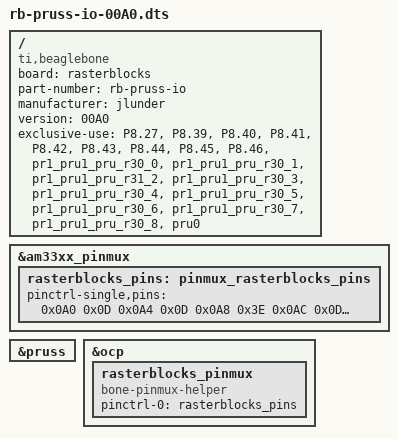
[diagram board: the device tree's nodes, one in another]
/dts-v1/;
/plugin/;

/ {
	compatible = "ti,beaglebone", "ti,beaglebone-black";
	board = "rasterblocks";
	part-number = "rb-pruss-io";
	manufacturer = "jlunder";
	version = "00A0";

	exclusive-use =
		"P8.27",
		"P8.39",
		"P8.40",
		"P8.41",
		"P8.42",
		"P8.43",
		"P8.44",
		"P8.45",
		"P8.46",
		"pr1_pru1_pru_r30_0",
		"pr1_pru1_pru_r30_1",
		"pr1_pru1_pru_r31_2",
		"pr1_pru1_pru_r30_3",
		"pr1_pru1_pru_r30_4",
		"pr1_pru1_pru_r30_5",
		"pr1_pru1_pru_r30_6",
		"pr1_pru1_pru_r30_7",
		"pr1_pru1_pru_r30_8",
		"pru0";

	fragment@0 {
		target = <&am33xx_pinmux>;
		__overlay__ {
			rasterblocks_pins: pinmux_rasterblocks_pins {
				pinctrl-single,pins = <
					0x0A0 0x0D  // P8_45: Mode 5 = pr1_pru1_pru_r30, disable pulldown, rx
					0x0A4 0x0D  // P8_46: Mode 5 = pr1_pru1_pru_r30, disable pulldown, rx
					0x0A8 0x3E  // P8_43: Mode 6 = pr1_pru1_pru_r31, disable pullup, enable rx
					0x0AC 0x0D  // P8_44: Mode 5 = pr1_pru1_pru_r30, disable pulldown, rx
					0x0B0 0x0D  // P8_41: Mode 5 = pr1_pru1_pru_r30, disable pulldown, rx
					0x0B4 0x0D  // P8_42: Mode 5 = pr1_pru1_pru_r30, disable pulldown, rx
					0x0B8 0x0D  // P8_39: Mode 5 = pr1_pru1_pru_r30, disable pulldown, rx
					0x0BC 0x0D  // P8_40: Mode 5 = pr1_pru1_pru_r30, disable pulldown, rx
					0x0E0 0x0D  // P8_27: Mode 5 = pr1_pru1_pru_r30, disable pulldown, rx
					>;
			};
		};
	};

	fragment@1 {
		target = <&pruss>;
		__overlay__ {
			status = "okay";
		};
	};

	fragment@2 {
		target = <&ocp>;
		__overlay__ {
			rasterblocks_pinmux {
				compatible = "bone-pinmux-helper";
				status = "okay";
				pinctrl-names = "default";
				pinctrl-0 = <&rasterblocks_pins>;
			};
		};
	};
};
